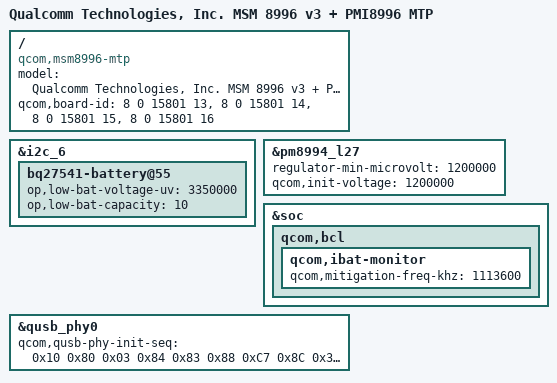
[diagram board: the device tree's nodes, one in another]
/* Copyright (c) 2015, The Linux Foundation. All rights reserved.
 *
 * This program is free software; you can redistribute it and/or modify
 * it under the terms of the GNU General Public License version 2 and
 * only version 2 as published by the Free Software Foundation.
 *
 * This program is distributed in the hope that it will be useful,
 * but WITHOUT ANY WARRANTY; without even the implied warranty of
 * MERCHANTABILITY or FITNESS FOR A PARTICULAR PURPOSE.  See the
 * GNU General Public License for more details.
 */


/dts-v1/;

#include "msm8996-v3.dtsi"
#include "msm-pmi8996.dtsi"
#include "15801/msm8996-mtp.dtsi"
#include "15801/msm8996-camera-sensor-mtp-15801.dtsi"

/ {
	model = "Qualcomm Technologies, Inc. MSM 8996 v3 + PMI8996 MTP";
	compatible = "qcom,msm8996-mtp", "qcom,msm8996", "qcom,mtp";
	qcom,board-id = <8 0 15801 13>, <8 0 15801 14>, <8 0 15801 15>, <8 0 15801 16>;
};

&i2c_6 {
	bq27541-battery@55 {
		op,low-bat-voltage-uv=<3350000>;
		op,low-bat-capacity=<10>;
	};
};

&pm8994_l27 {
	regulator-min-microvolt = <1200000>;
	qcom,init-voltage = <1200000>;
};

&soc {
	qcom,bcl {
		qcom,ibat-monitor {
			qcom,mitigation-freq-khz = <1113600>;
		};
	};
};

&qusb_phy0 {
	qcom,qusb-phy-init-seq = <0x10 0x80
				0x03 0x84
				0x83 0x88
				0xC7 0x8C
				0x30 0x08
				0x79 0x0C
				0x21 0x10
				0x14 0x9C
				0x80 0x04
				0x9F 0x1C
				0x00 0x18>;
};
